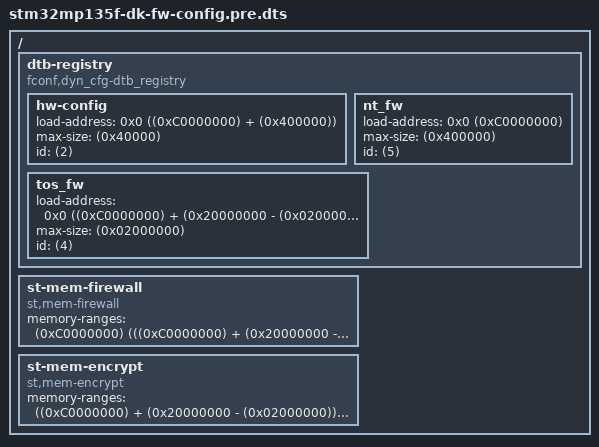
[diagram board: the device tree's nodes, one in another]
/dts-v1/;
/ {
 dtb-registry {
  compatible = "fconf,dyn_cfg-dtb_registry";
  hw-config {
   load-address = <0x0 ((0xC0000000) + (0x400000))>;
   max-size = <(0x40000)>;
   id = <(2)>;
  };
  nt_fw {
   load-address = <0x0 (0xC0000000)>;
   max-size = <(0x400000)>;
   id = <(5)>;
  };
  tos_fw {
   load-address = <0x0 ((0xC0000000) + (0x20000000 - (0x02000000)))>;
   max-size = <(0x02000000)>;
   id = <(4)>;
  };
 };
 st-mem-firewall {
  compatible = "st,mem-firewall";
  memory-ranges = <
   (0xC0000000) (((0xC0000000) + (0x20000000 - (0x02000000))) - (0xC0000000)) (0) (((((1) << (((0)) & (0xf))) << 0) | (((1) << (((0)) & (0xf))) << 16)) | ((((1) << (((3)) & (0xf))) << 0) | (((1) << (((3)) & (0xf))) << 16)) | ((((1) << (((5)) & (0xf))) << 0) | (((1) << (((5)) & (0xf))) << 16)) | ((((1) << (((6)) & (0xf))) << 0) | (((1) << (((6)) & (0xf))) << 16)) | ((((1) << (((7)) & (0xf))) << 0) | (((1) << (((7)) & (0xf))) << 16)) | ((((1) << (((8)) & (0xf))) << 0) | (((1) << (((8)) & (0xf))) << 16)) | ((((1) << (((9)) & (0xf))) << 0) | (((1) << (((9)) & (0xf))) << 16)) | ((((1) << (((10)) & (0xf))) << 0) | (((1) << (((10)) & (0xf))) << 16)) | ((((1) << (((11)) & (0xf))) << 0) | (((1) << (((11)) & (0xf))) << 16)) | ((((1) << (((15)) & (0xf))) << 0) | (((1) << (((15)) & (0xf))) << 16)))
   ((0xC0000000) + (0x20000000 - (0x02000000))) (0x02000000) ((1) | (2)) 0>;
 };
};
/ {
 st-mem-encrypt {
  compatible = "st,mem-encrypt";
  memory-ranges = <((0xC0000000) + (0x20000000 - (0x02000000))) (0x02000000) (1)>;
 };
};
